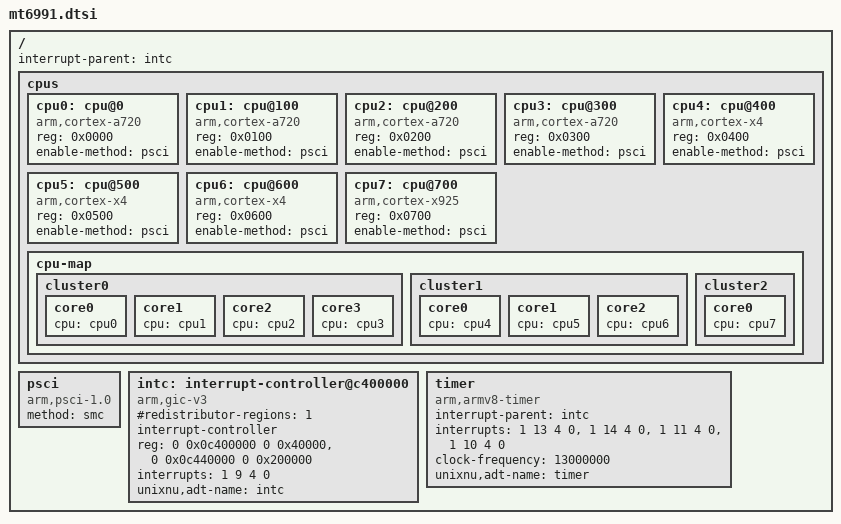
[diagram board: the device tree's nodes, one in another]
/*
 * Partial shared MT6991 inputs from Dali's read-only live FDT capture.
 * Capture SHA-256: b1e31720e948e8769a2fcb7fd9a097c30b934200b8033692f9ed1214b1985182
 * CPU compatible values below are derived from the public Dimensity 9400 core
 * mix and reference DTS revision e45c3199537fbba9aae5fb06c31fc8dbd3c1dcee's
 * 4/3/1 CPU map plus PMU cluster names.
 * The live FDT does not provide per-core compatibles or MIDRs. DRAM remains
 * intentionally omitted; see docs/hardware-inputs.md.
 */

/ {
	#address-cells = <2>;
	#size-cells = <2>;
	interrupt-parent = <&intc>;

	cpus {
		#address-cells = <1>;
		#size-cells = <0>;

		cpu0: cpu@0 {
			device_type = "cpu";
			compatible = "arm,cortex-a720";
			reg = <0x0000>;
			enable-method = "psci";
		};

		cpu1: cpu@100 {
			device_type = "cpu";
			compatible = "arm,cortex-a720";
			reg = <0x0100>;
			enable-method = "psci";
		};

		cpu2: cpu@200 {
			device_type = "cpu";
			compatible = "arm,cortex-a720";
			reg = <0x0200>;
			enable-method = "psci";
		};

		cpu3: cpu@300 {
			device_type = "cpu";
			compatible = "arm,cortex-a720";
			reg = <0x0300>;
			enable-method = "psci";
		};

		cpu4: cpu@400 {
			device_type = "cpu";
			compatible = "arm,cortex-x4";
			reg = <0x0400>;
			enable-method = "psci";
		};

		cpu5: cpu@500 {
			device_type = "cpu";
			compatible = "arm,cortex-x4";
			reg = <0x0500>;
			enable-method = "psci";
		};

		cpu6: cpu@600 {
			device_type = "cpu";
			compatible = "arm,cortex-x4";
			reg = <0x0600>;
			enable-method = "psci";
		};

		cpu7: cpu@700 {
			device_type = "cpu";
			compatible = "arm,cortex-x925";
			reg = <0x0700>;
			enable-method = "psci";
		};

		cpu-map {
			cluster0 {
				core0 { cpu = <&cpu0>; };
				core1 { cpu = <&cpu1>; };
				core2 { cpu = <&cpu2>; };
				core3 { cpu = <&cpu3>; };
			};
			cluster1 {
				core0 { cpu = <&cpu4>; };
				core1 { cpu = <&cpu5>; };
				core2 { cpu = <&cpu6>; };
			};
			cluster2 {
				core0 { cpu = <&cpu7>; };
			};
		};
	};

	psci {
		compatible = "arm,psci-1.0";
		method = "smc";
	};

	intc: interrupt-controller@c400000 {
		compatible = "arm,gic-v3";
		#interrupt-cells = <4>;
		#address-cells = <2>;
		#size-cells = <2>;
		#redistributor-regions = <1>;
		interrupt-controller;
		reg = <0 0x0c400000 0 0x40000>,
		      <0 0x0c440000 0 0x200000>;
		interrupts = <1 9 4 0>;
		unixnu,adt-name = "intc";
	};

	timer {
		compatible = "arm,armv8-timer";
		interrupt-parent = <&intc>;
		interrupts = <1 13 4 0>, <1 14 4 0>, <1 11 4 0>, <1 10 4 0>;
		clock-frequency = <13000000>;
		unixnu,adt-name = "timer";
	};
};
